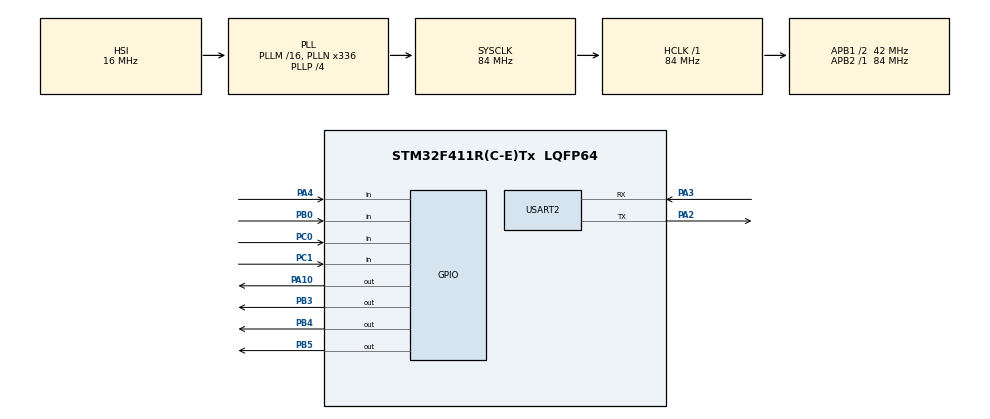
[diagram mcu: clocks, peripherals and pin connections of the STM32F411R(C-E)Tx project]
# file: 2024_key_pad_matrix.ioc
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Mcu.Family=STM32F4
Mcu.Name=STM32F411R(C-E)Tx
Mcu.Package=LQFP64
NVIC.PriorityGroup=NVIC_PRIORITYGROUP_0
PA10.GPIO_ModeDefaultOutputPP=GPIO_MODE_OUTPUT_PP
PA10.GPIO_PuPd=GPIO_PULLDOWN
PA10.GPIO_Speed=GPIO_SPEED_FREQ_HIGH
PA10.PinState=GPIO_PIN_SET
PA10.Signal=GPIO_Output
PA13.GPIO_Label=TMS
PA13.Mode=Serial_Wire
PA13.Signal=SYS_JTMS-SWDIO
PA14.GPIO_Label=TCK
PA14.Mode=Serial_Wire
PA14.Signal=SYS_JTCK-SWCLK
PA2.Mode=Asynchronous
PA2.Signal=USART2_TX
PA3.Mode=Asynchronous
PA3.Signal=USART2_RX
PA4.GPIO_PuPd=GPIO_PULLDOWN
PA4.Signal=GPIO_Input
PB0.GPIO_PuPd=GPIO_PULLDOWN
PB0.Signal=GPIO_Input
PB3.GPIO_PuPd=GPIO_PULLDOWN
PB3.GPIO_Speed=GPIO_SPEED_FREQ_HIGH
PB3.PinState=GPIO_PIN_SET
PB3.Signal=GPIO_Output
PB4.GPIO_PuPd=GPIO_PULLDOWN
PB4.GPIO_Speed=GPIO_SPEED_FREQ_HIGH
PB4.PinState=GPIO_PIN_SET
PB4.Signal=GPIO_Output
PB5.GPIO_PuPd=GPIO_PULLDOWN
PB5.GPIO_Speed=GPIO_SPEED_FREQ_HIGH
PB5.PinState=GPIO_PIN_SET
PB5.Signal=GPIO_Output
PC0.GPIO_PuPd=GPIO_PULLDOWN
PC0.Signal=GPIO_Input
PC1.GPIO_PuPd=GPIO_PULLDOWN
PC1.Signal=GPIO_Input
PC14-OSC32_IN.Mode=LSE-External-Oscillator
PC14-OSC32_IN.Signal=RCC_OSC32_IN
PC15-OSC32_OUT.Mode=LSE-External-Oscillator
PC15-OSC32_OUT.Signal=RCC_OSC32_OUT
PH0\ -\ OSC_IN.Mode=HSE-External-Clock-Source
PH0\ -\ OSC_IN.Signal=RCC_OSC_IN
PH1\ -\ OSC_OUT.Mode=HSE-External-Clock-Source
PH1\ -\ OSC_OUT.Signal=RCC_OSC_OUT
ProjectManager.HeapSize=0x200
ProjectManager.StackSize=0x400
ProjectManager.TargetToolchain=STM32CubeIDE
RCC.48MHZClocksFreq_Value=84000000
RCC.AHBFreq_Value=84000000
RCC.APB1CLKDivider=RCC_HCLK_DIV2
RCC.APB1Freq_Value=42000000
RCC.APB1TimFreq_Value=84000000
RCC.APB2Freq_Value=84000000
RCC.APB2TimFreq_Value=84000000
RCC.CortexFreq_Value=84000000
RCC.FLatency-AdvancedSettings=FLASH_LATENCY_2
RCC.HCLKFreq_Value=84000000
RCC.HSE_VALUE=8000000
RCC.HSI_VALUE=16000000
RCC.PLLN=336
RCC.PLLP=RCC_PLLP_DIV4
RCC.SYSCLKFreq_VALUE=84000000
RCC.SYSCLKSource=RCC_SYSCLKSOURCE_PLLCLK
RCC.VCOOutputFreq_Value=336000000
USART2.VirtualMode=VM_ASYNC
board=NUCLEO-F411RE

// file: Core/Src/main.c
/* USER CODE BEGIN Header */
/**
 ******************************************************************************
 * @file           : main.c
 * @brief          : Main program body
 ******************************************************************************
 * @attention
 *
 * Copyright (c) 2024 STMicroelectronics.
 * All rights reserved.
 *
 * This software is licensed under terms that can be found in the LICENSE file
 * in the root directory of this software component.
 * If no LICENSE file comes with this software, it is provided AS-IS.
 *
 ******************************************************************************
 */
/* USER CODE END Header */
#include "main.h"
#include <stdio.h>		//for sprintf

/* USER CODE BEGIN PM */
uint8_t msg1[] = "Enter the code and press 'D' \n\r";
/* USER CODE END PM */

UART_HandleTypeDef huart2;

/* USER CODE BEGIN PV */
char buffer[80];
int i;	//when we prees the button, the 'i' will be align to pressed digit
int DigitCounter;	//count how many times push the button, if you press enter, it will be align to 0
int pressedDigit;	// digit number which you pressed, if you pres 'number 3', pressedDigit will be 3
int enter;	// it comes to 99 when you press 'D' on matrix
int entered[3];	// it saves 4 first values of entered code
int code[] = { 3, 6, 9, 3 };	//there is our valid code
/* USER CODE END PV */

void SystemClock_Config(void);
static void MX_GPIO_Init(void);
static void MX_USART2_UART_Init(void);

int main(void) {

	/* MCU Configuration--------------------------------------------------------*/

	/* Reset of all peripherals, Initializes the Flash interface and the Systick. */
	HAL_Init();

	/* Configure the system clock */
	SystemClock_Config();

	/* Initialize all configured peripherals */
	MX_GPIO_Init();
	MX_USART2_UART_Init();
	/* USER CODE BEGIN 2 */
	HAL_UART_Transmit(&huart2, msg1, sizeof(msg1), 1000);

	/* USER CODE END 2 */

	/* Infinite loop */
	while (1) {
//column 1
		HAL_GPIO_WritePin(GPIOA, GPIO_PIN_10, GPIO_PIN_SET);

		if (HAL_GPIO_ReadPin(GPIOA, GPIO_PIN_10) != GPIO_PIN_RESET) {

			if (HAL_GPIO_ReadPin(GPIOC, GPIO_PIN_0) == GPIO_PIN_SET) {
				while (HAL_GPIO_ReadPin(GPIOC, GPIO_PIN_0) == GPIO_PIN_SET) {
				}
				pressedDigit = 1;
				DigitCounter++;
			}

			if (HAL_GPIO_ReadPin(GPIOC, GPIO_PIN_1) == GPIO_PIN_SET) {
				while (HAL_GPIO_ReadPin(GPIOC, GPIO_PIN_1) == GPIO_PIN_SET) {
				}
				pressedDigit = 4;
				DigitCounter++;
			}

			if (HAL_GPIO_ReadPin(GPIOB, GPIO_PIN_0) == GPIO_PIN_SET) {
				while (HAL_GPIO_ReadPin(GPIOB, GPIO_PIN_0) == GPIO_PIN_SET) {
				}
				pressedDigit = 7;
				DigitCounter++;
			}

			HAL_GPIO_WritePin(GPIOA, GPIO_PIN_10, GPIO_PIN_RESET);
			HAL_Delay(5);
		}

		//------------------------
		//column 3

		HAL_GPIO_WritePin(GPIOB, GPIO_PIN_3, GPIO_PIN_SET);
		if (HAL_GPIO_ReadPin(GPIOB, GPIO_PIN_3) != GPIO_PIN_RESET) {

			if (HAL_GPIO_ReadPin(GPIOC, GPIO_PIN_0) == GPIO_PIN_SET) {
				while (HAL_GPIO_ReadPin(GPIOC, GPIO_PIN_0) == GPIO_PIN_SET) {
				}
				pressedDigit = 3;
				DigitCounter++;
			}

			if (HAL_GPIO_ReadPin(GPIOC, GPIO_PIN_1) == GPIO_PIN_SET) {
				while (HAL_GPIO_ReadPin(GPIOC, GPIO_PIN_1) == GPIO_PIN_SET) {
				}
				pressedDigit = 6;
				DigitCounter++;
			}

			if (HAL_GPIO_ReadPin(GPIOB, GPIO_PIN_0) == GPIO_PIN_SET) {
				while (HAL_GPIO_ReadPin(GPIOB, GPIO_PIN_0) == GPIO_PIN_SET) {
				}
				pressedDigit = 9;
				DigitCounter++;
			}

			HAL_GPIO_WritePin(GPIOB, GPIO_PIN_3, GPIO_PIN_RESET);
			HAL_Delay(5);

		}
//-------------------------------
		//column 2

		HAL_GPIO_WritePin(GPIOB, GPIO_PIN_5, GPIO_PIN_SET);

		if (HAL_GPIO_ReadPin(GPIOB, GPIO_PIN_5) != GPIO_PIN_RESET) {

			if (HAL_GPIO_ReadPin(GPIOC, GPIO_PIN_0) == GPIO_PIN_SET) {
				while (HAL_GPIO_ReadPin(GPIOC, GPIO_PIN_0) == GPIO_PIN_SET) {
				}

				pressedDigit = 2;
				DigitCounter++;
			}

			if (HAL_GPIO_ReadPin(GPIOC, GPIO_PIN_1) == GPIO_PIN_SET) {
				while (HAL_GPIO_ReadPin(GPIOC, GPIO_PIN_1) == GPIO_PIN_SET) {
				}
				pressedDigit = 5;
				DigitCounter++;
			}

			if (HAL_GPIO_ReadPin(GPIOB, GPIO_PIN_0) == GPIO_PIN_SET) {
				while (HAL_GPIO_ReadPin(GPIOB, GPIO_PIN_0) == GPIO_PIN_SET) {
				}
				pressedDigit = 8;
				DigitCounter++;
			}

			if (HAL_GPIO_ReadPin(GPIOA, GPIO_PIN_4) == GPIO_PIN_SET) {
				while (HAL_GPIO_ReadPin(GPIOA, GPIO_PIN_4) == GPIO_PIN_SET) {
				}
				pressedDigit = 0;
				DigitCounter++;
			}
			HAL_GPIO_WritePin(GPIOB, GPIO_PIN_5, GPIO_PIN_RESET);
			HAL_Delay(5);

		}
		//-----------------------
		//column 4

		HAL_GPIO_WritePin(GPIOB, GPIO_PIN_4, GPIO_PIN_SET);

		if (HAL_GPIO_ReadPin(GPIOB, GPIO_PIN_4) != GPIO_PIN_RESET) {

			if (HAL_GPIO_ReadPin(GPIOA, GPIO_PIN_4) == GPIO_PIN_SET) {
				while (HAL_GPIO_ReadPin(GPIOA, GPIO_PIN_4) == GPIO_PIN_SET) {
					//if you press 'D', then-->
					enter = 99;
				}
			}
			HAL_GPIO_WritePin(GPIOB, GPIO_PIN_4, GPIO_PIN_RESET);
			HAL_Delay(5);

		}
		if (i != pressedDigit) {
			snprintf(buffer, 100, "%d", pressedDigit);
			HAL_UART_Transmit(&huart2, (uint8_t*) buffer, sizeof(buffer), 1000);
			i = pressedDigit;
		}
		if (DigitCounter == 1) {
			entered[0] = pressedDigit;
		}
		if (DigitCounter == 2) {
			entered[1] = pressedDigit;
		}
		if (DigitCounter == 3) {
			entered[2] = pressedDigit;
		}
		if (DigitCounter == 4) {
			entered[3] = pressedDigit;
		}

		//entered Code:
		if (enter == 99) {
			snprintf(buffer, 100, "\n \r entered code : \n\r");
			HAL_UART_Transmit(&huart2, (uint8_t*) buffer, sizeof(buffer), 1000);
			enter = 0;
			HAL_Delay(5);

			snprintf(buffer, 100,
					"                                                \n\r");
			snprintf(buffer, 100, "%d%d%d%d ", entered[0], entered[1],
					entered[2], entered[3]);
			HAL_UART_Transmit(&huart2, (uint8_t*) buffer, sizeof(buffer), 1000);
			if (entered[0] == code[0] & entered[1] == code[1]
					& entered[2] == code[2] & entered[3] == code[3]) {
				snprintf(buffer, 100, "\n \r Validate :) !! \n\r");
				HAL_UART_Transmit(&huart2, (uint8_t*) buffer, sizeof(buffer),
						1000);
			}
			if (entered[0] != code[0] | entered[1] != code[1]
					| entered[2] != code[2] | entered[3] != code[3]) {
				snprintf(buffer, 100, "\n \r Bad code :( \n\r");
				HAL_UART_Transmit(&huart2, (uint8_t*) buffer, sizeof(buffer),
						1000);
				snprintf(buffer, 100, "\n \r LET'S TRY AGAIN.. \n\r");
				HAL_UART_Transmit(&huart2, (uint8_t*) buffer, sizeof(buffer),
						1000);
				DigitCounter = 0;
				i = 0;
				pressedDigit = 0;
			}
		}
	}
}

void SystemClock_Config(void) {
	RCC_OscInitTypeDef RCC_OscInitStruct = { 0 };
	RCC_ClkInitTypeDef RCC_ClkInitStruct = { 0 };

	/** Configure the main internal regulator output voltage
	 */
	__HAL_RCC_PWR_CLK_ENABLE();
	__HAL_PWR_VOLTAGESCALING_CONFIG(PWR_REGULATOR_VOLTAGE_SCALE1);

	/** Initializes the RCC Oscillators according to the specified parameters
	 * in the RCC_OscInitTypeDef structure.
	 */
	RCC_OscInitStruct.OscillatorType = RCC_OSCILLATORTYPE_HSI;
	RCC_OscInitStruct.HSIState = RCC_HSI_ON;
	RCC_OscInitStruct.HSICalibrationValue = RCC_HSICALIBRATION_DEFAULT;
	RCC_OscInitStruct.PLL.PLLState = RCC_PLL_ON;
	RCC_OscInitStruct.PLL.PLLSource = RCC_PLLSOURCE_HSI;
	RCC_OscInitStruct.PLL.PLLM = 16;
	RCC_OscInitStruct.PLL.PLLN = 336;
	RCC_OscInitStruct.PLL.PLLP = RCC_PLLP_DIV4;
	RCC_OscInitStruct.PLL.PLLQ = 4;
	if (HAL_RCC_OscConfig(&RCC_OscInitStruct) != HAL_OK) {
		Error_Handler();
	}

	/** Initializes the CPU, AHB and APB buses clocks
	 */
	RCC_ClkInitStruct.ClockType = RCC_CLOCKTYPE_HCLK | RCC_CLOCKTYPE_SYSCLK
			| RCC_CLOCKTYPE_PCLK1 | RCC_CLOCKTYPE_PCLK2;
	RCC_ClkInitStruct.SYSCLKSource = RCC_SYSCLKSOURCE_PLLCLK;
	RCC_ClkInitStruct.AHBCLKDivider = RCC_SYSCLK_DIV1;
	RCC_ClkInitStruct.APB1CLKDivider = RCC_HCLK_DIV2;
	RCC_ClkInitStruct.APB2CLKDivider = RCC_HCLK_DIV1;

	if (HAL_RCC_ClockConfig(&RCC_ClkInitStruct, FLASH_LATENCY_2) != HAL_OK) {
		Error_Handler();
	}
}

static void MX_USART2_UART_Init(void) {

	huart2.Instance = USART2;
	huart2.Init.BaudRate = 115200;
	huart2.Init.WordLength = UART_WORDLENGTH_8B;
	huart2.Init.StopBits = UART_STOPBITS_1;
	huart2.Init.Parity = UART_PARITY_NONE;
	huart2.Init.Mode = UART_MODE_TX_RX;
	huart2.Init.HwFlowCtl = UART_HWCONTROL_NONE;
	huart2.Init.OverSampling = UART_OVERSAMPLING_16;
	if (HAL_UART_Init(&huart2) != HAL_OK) {
		Error_Handler();
	}

}

static void MX_GPIO_Init(void) {
	GPIO_InitTypeDef GPIO_InitStruct = { 0 };

	/* GPIO Ports Clock Enable */
	__HAL_RCC_GPIOC_CLK_ENABLE();
	__HAL_RCC_GPIOH_CLK_ENABLE();
	__HAL_RCC_GPIOA_CLK_ENABLE();
	__HAL_RCC_GPIOB_CLK_ENABLE();

	/*Configure GPIO pin Output Level */
	HAL_GPIO_WritePin(GPIOA, GPIO_PIN_10, GPIO_PIN_SET);

	/*Configure GPIO pin Output Level */
	HAL_GPIO_WritePin(GPIOB, GPIO_PIN_3 | GPIO_PIN_4 | GPIO_PIN_5,
			GPIO_PIN_SET);

	/*Configure GPIO pins : PC0 PC1 */
	GPIO_InitStruct.Pin = GPIO_PIN_0 | GPIO_PIN_1;
	GPIO_InitStruct.Mode = GPIO_MODE_INPUT;
	GPIO_InitStruct.Pull = GPIO_PULLDOWN;
	HAL_GPIO_Init(GPIOC, &GPIO_InitStruct);

	/*Configure GPIO pin : PA4 */
	GPIO_InitStruct.Pin = GPIO_PIN_4;
	GPIO_InitStruct.Mode = GPIO_MODE_INPUT;
	GPIO_InitStruct.Pull = GPIO_PULLDOWN;
	HAL_GPIO_Init(GPIOA, &GPIO_InitStruct);

	/*Configure GPIO pin : PB0 */
	GPIO_InitStruct.Pin = GPIO_PIN_0;
	GPIO_InitStruct.Mode = GPIO_MODE_INPUT;
	GPIO_InitStruct.Pull = GPIO_PULLDOWN;
	HAL_GPIO_Init(GPIOB, &GPIO_InitStruct);

	/*Configure GPIO pin : PA10 */
	GPIO_InitStruct.Pin = GPIO_PIN_10;
	GPIO_InitStruct.Mode = GPIO_MODE_OUTPUT_PP;
	GPIO_InitStruct.Pull = GPIO_PULLDOWN;
	GPIO_InitStruct.Speed = GPIO_SPEED_FREQ_HIGH;
	HAL_GPIO_Init(GPIOA, &GPIO_InitStruct);

	/*Configure GPIO pins : PB3 PB4 PB5 */
	GPIO_InitStruct.Pin = GPIO_PIN_3 | GPIO_PIN_4 | GPIO_PIN_5;
	GPIO_InitStruct.Mode = GPIO_MODE_OUTPUT_PP;
	GPIO_InitStruct.Pull = GPIO_PULLDOWN;
	GPIO_InitStruct.Speed = GPIO_SPEED_FREQ_HIGH;
	HAL_GPIO_Init(GPIOB, &GPIO_InitStruct);

}

void Error_Handler(void) {
	__disable_irq();
	while (1) {
	}
}
